# sem register map
Vendor: Texas Instruments
Peripheral module from a debugger description file (folder Keystone).
Registers are 32-bit, access per field, no defined reset value unless marked. A register's access mark holds for its fields unless they carry their own. Offsets are as the file gives them; lines under a group give offsets from that group; [hi:lo] are bit positions; {n}, {i} and the like mark numbered series; 'fields as' and 'values as' point back to an identical list; <NAME> marks a mode.

## SEM
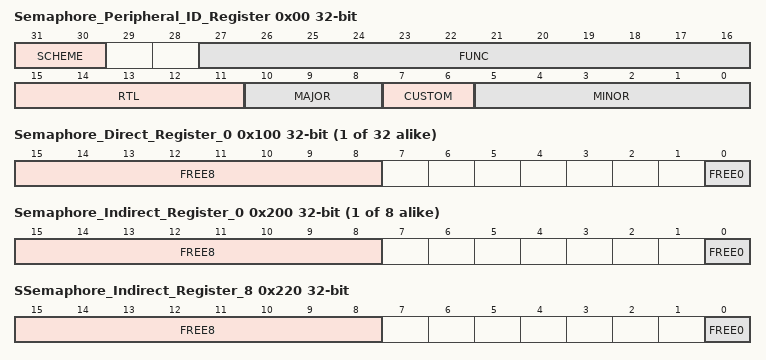
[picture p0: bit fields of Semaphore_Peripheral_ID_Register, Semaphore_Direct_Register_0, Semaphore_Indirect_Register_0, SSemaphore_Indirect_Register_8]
0x00 Semaphore_Peripheral_ID_Register
  [31:30] SCHEME ro — PID Scheme
  [27:16] FUNC ro — Func indicates a software compatible family
  [15:11] RTL ro — RTL Version
  [10:8] MAJOR ro — Major Revision Number
  [7:6] CUSTOM rw — Not used on EDMA
  [5:0] MINOR ro — Minor Revision Number
0x04 Semaphore_Scratch_Register rw
  [31:0] SCRATCH — Scratch value for testing vbusp access
0x08 Semaphore_Reset_Run_status_Register ro
  [0] RESET_RUN — Write 1 soft reset, Read 1 ready
0x0C Semaphore_EOI_Register wo
  [7:0] EOI — Interrupt End of Interrupt
{0x100+4i} Semaphore_Direct_Register_{i} (i=0..31)
  [15:8] FREE8 ro — Semaphore resource owner when free = 0
  [0] FREE0 rw — Direct Semaphore flag control, read/write action
{0x200+4i} Semaphore_Indirect_Register_{i} (i=0..7)
  [15:8] FREE8 ro — Semaphore resource owner when free = 0
  [0] FREE0 rw — Indirect Semaphore flag control, read/write action
0x220 SSemaphore_Indirect_Register_8
  fields as Semaphore_Indirect_Register_0
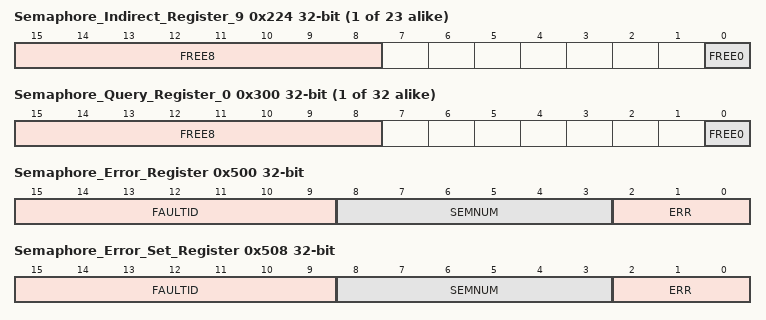
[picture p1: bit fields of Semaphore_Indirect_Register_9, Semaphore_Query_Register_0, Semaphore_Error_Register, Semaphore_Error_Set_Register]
{0x200+4i} Semaphore_Indirect_Register_{i} (i=9..31)
  fields as Semaphore_Indirect_Register_0
{0x300+4i} Semaphore_Query_Register_{i} (i=0..31)
  [15:8] FREE8 ro — Semaphore resource owner when free = 0
  [0] FREE0 rw — Semaphore flag query and control, read/write action
{0x400+4i} Semaphore_Flag_Register{i} ro (i=0..3)
  [0] FLAG{n} (n=0..31) — Semaphore flag {n}
{0x400+4i} Semaphore_Flag_Clear_Register{i} wo (i=0..3)
  [0] FLAG{n} (n=0..31) — Semaphore Flag Clear {n}
{0x480+4i} Semaphore_Flag_Set_Register{i} wo (i=0..3)
  [0] FLAG{n} (n=0..31) — Semaphore Flag Set {n}
0x500 Semaphore_Error_Register ro
  [15:9] FAULTID — Master that caused the error
  [8:3] SEMNUM — Semaphore Number
  [2:0] ERR — Semaphore error code
0x504 Semaphore_Error_Clear_Register wo
  [0] CLRERR — Clear Semaphore error register =1, no affect =0
0x508 Semaphore_Error_Set_Register wo
  [15:9] FAULTID — Set Master that caused the error
  [8:3] SEMNUM — Set Semaphore Number
  [2:0] ERR — Set Semaphore error code
